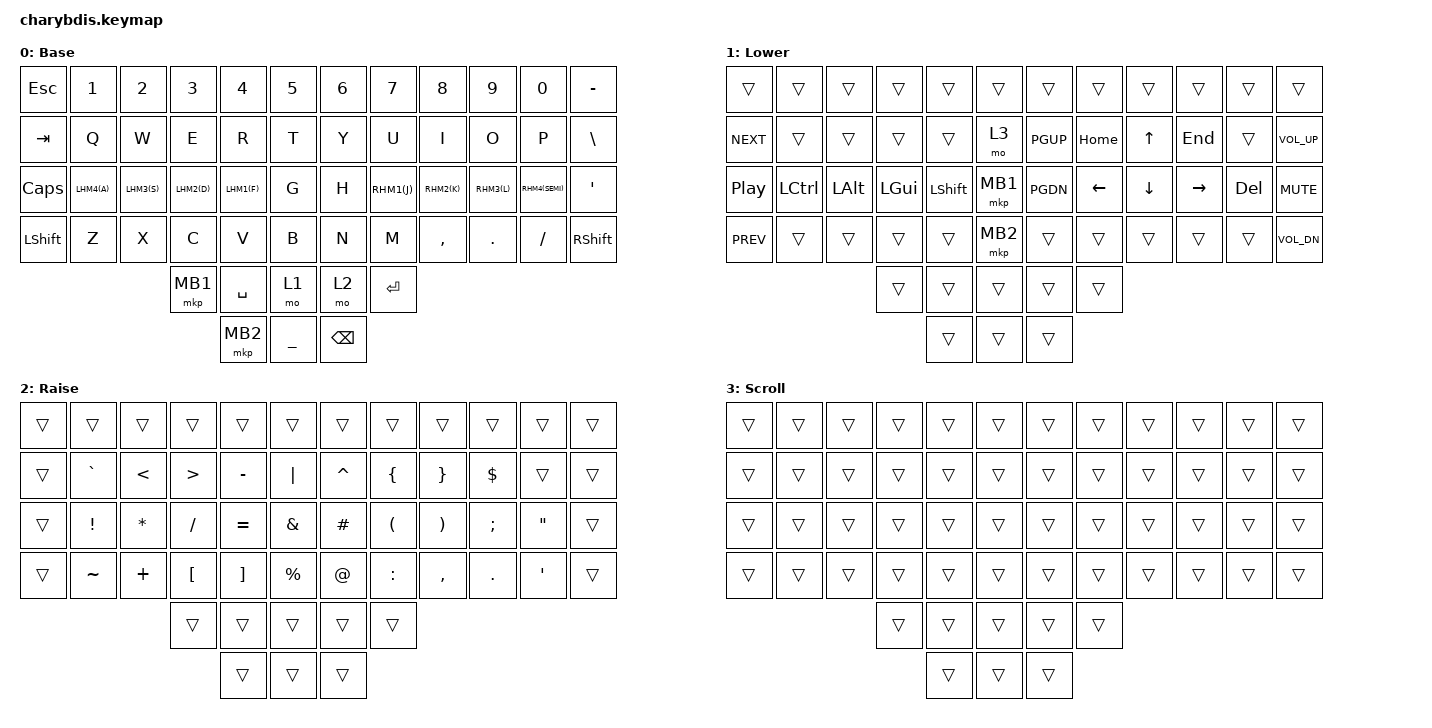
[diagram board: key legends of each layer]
#include <behaviors.dtsi>
#include <dt-bindings/zmk/bt.h>
#include <dt-bindings/zmk/keys.h>
#include <dt-bindings/zmk/pointing.h>
#include <zephyr/dt-bindings/input/input-event-codes.h>

/* KEY POSITIONS
  ╭───────────────────╮ ╭───────────────────╮
  │  0  1  3  4  5  6 │ │  7  8  9 10 11 12 │
  │ 12 13 14 15 16 17 │ │ 18 19 20 21 22 23 │
  │ 24 25 26 27 28 29 │ │ 30 31 32 33 34 35 │
  │ 36 37 38 39 40 41 │ │ 42 43 44 45 46 47 │
  ╰────────╮ 48 49 50 │ │ 51 52 ╭───────────╯
           ╰──╮ 53 54 | | 55 ╭──╯
              ╰───────╯ ╰────╯ */

/* Global defaults */

#define QUICK_TAP_MS 175

/* Homerow mods */

#define KEYS_L  0  1  2  3  4  5 12 13 14 15 16 17 24 25 26 27 28 29 36 37 38 39 40 41
#define KEYS_R  6  7  8  9 10 11 18 19 20 21 22 23 30 31 32 33 34 35 42 43 44 45 46 47
#define THUMBS 48 49 50 51 52 53 54 55

// Finger importance: 1=Index, 2=Middle, 3=Ring, 4=Pinky
// Left side
#define LHRM1 LSHFT
#define LHRM2 LGUI
#define LHRM3 LALT
#define LHRM4 LCTRL

// Right side
#define RHRM1 RSHFT
#define RHRM2 RGUI
#define RHRM3 RALT
#define RHRM4 RCTRL

// Behavior-calling macros for home row mods
// Left side
#define LHM1(_key)  &hml LHRM1 _key
#define LHM2(_key)  &hml LHRM2 _key
#define LHM3(_key)  &hml LHRM3 _key
#define LHM4(_key)  &hml LHRM4 _key

// Right side
#define RHM1(_key)  &hmr RHRM1 _key
#define RHM2(_key)  &hmr RHRM2 _key
#define RHM3(_key)  &hmr RHRM3 _key
#define RHM4(_key)  &hmr RHRM4 _key

// Helper macro to define home-row modifier behaviors
#define DEFINE_HRM(_label, _name, _hold, _tap, _triggers, ...)  \
    _label: _name {                                             \
      compatible = "zmk,behavior-hold-tap";                     \
      label = #_name;                                           \
      #binding-cells = <2>;                                     \
      flavor = "balanced";                                      \
      tapping-term-ms = <200>;                                  \
      quick-tap-ms = <QUICK_TAP_MS>;                            \
      require-prior-idle-ms = <125>;                            \
      hold-trigger-key-positions = <_triggers>;                 \
      hold-trigger-on-release;                                  \
      bindings = <_hold>, <_tap>;                               \
      __VA_ARGS__                                               \
    }

&lt {
    tapping-term-ms = <200>;
    flavor = "balanced";
    quick-tap-ms = <QUICK_TAP_MS>;
};

/ {
    combos {
        compatible = "zmk,combos";
        combo_mouse_drag {
            timeout-ms = <50>;
            key-positions = <48 53>;
            bindings = <&mo 3>;
        };
    };

    behaviors {
        DEFINE_HRM(hml, home_row_mod_left, &kp, &kp, KEYS_R THUMBS);
        DEFINE_HRM(hmr, home_row_mod_right, &kp, &kp, KEYS_L THUMBS);
    };

    keymap {
        compatible = "zmk,keymap";

        layer_0 {
           label = "Base";
           bindings = <
&kp ESC    &kp N1       &kp N2      &kp N3      &kp N4      &kp N5        &kp N6      &kp N7      &kp N8      &kp N9      &kp N0      &kp MINUS
&kp TAB    &kp Q        &kp W       &kp E       &kp R       &kp T         &kp Y       &kp U       &kp I       &kp O       &kp P       &kp BSLH
&kp CAPS   LHM4(A)      LHM3(S)     LHM2(D)     LHM1(F)     &kp G         &kp H       RHM1(J)     RHM2(K)     RHM3(L)     RHM4(SEMI)  &kp SQT
&kp LSHFT  &kp Z        &kp X       &kp C       &kp V       &kp B         &kp N       &kp M       &kp COMMA   &kp DOT     &kp FSLH    &kp RSHFT
                                    &mkp MB1    &kp SPACE   &mo 1         &mo 2       &kp ENTER
                                                &mkp MB2    &kp UNDER    &kp BSPC
            >;
        };

        layer_1 {
            label = "Lower";
            bindings = <

&trans      &trans      &trans      &trans      &trans      &trans        &trans      &trans      &trans      &trans      &trans      &trans
&kp C_NEXT  &trans      &trans      &trans      &trans      &mo 3         &kp PGUP    &kp HOME    &kp UP      &kp END     &trans      &kp C_VOL_UP
&kp C_PP    &kp LCTRL   &kp LALT    &kp LGUI    &kp LSHFT   &mkp MB1      &kp PGDN    &kp LEFT    &kp DOWN    &kp RIGHT   &kp DEL     &kp C_MUTE
&kp C_PREV  &trans      &trans      &trans      &trans      &mkp MB2      &trans      &trans      &trans      &trans      &trans      &kp C_VOL_DN
                                    &trans      &trans      &trans        &trans      &trans
                                                &trans      &trans        &trans
            >;
        };

        layer_2 {
            label = "Raise";
            bindings = <
&trans      &trans      &trans      &trans      &trans      &trans        &trans      &trans      &trans      &trans      &trans      &trans
&trans      &kp GRAVE   &kp LT      &kp GT      &kp MINUS   &kp PIPE      &kp CARET   &kp LBRC    &kp RBRC    &kp DLLR    &trans      &trans
&trans      &kp EXCL    &kp ASTRK   &kp SLASH   &kp EQUAL   &kp AMPS      &kp HASH    &kp LPAR    &kp RPAR    &kp SEMI    &kp DQT     &trans
&trans      &kp TILDE   &kp PLUS    &kp LBKT    &kp RBKT    &kp PRCNT     &kp AT      &kp COLON   &kp COMMA   &kp DOT     &kp SQT     &trans
                                    &trans      &trans      &trans        &trans      &trans
                                                &trans      &trans        &trans
            >;
        };

        layer_3 {
            label = "Scroll";
            bindings = <
&trans      &trans      &trans      &trans      &trans      &trans        &trans      &trans      &trans      &trans      &trans      &trans
&trans      &trans      &trans      &trans      &trans      &trans        &trans      &trans      &trans      &trans      &trans      &trans
&trans      &trans      &trans      &trans      &trans      &trans        &trans      &trans      &trans      &trans      &trans      &trans
&trans      &trans      &trans      &trans      &trans      &trans        &trans      &trans      &trans      &trans      &trans      &trans
                                    &trans      &trans      &trans        &trans      &trans
                                                &trans      &trans        &trans
            >;
        };
    };
};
